# cslr_usb_001 register map
Vendor: Texas Instruments
Address unit: 16 bits
Registers are 16-bit, access not given, reset 0x0 unless marked. A register's access mark holds for its fields unless they carry their own. Offsets are as the file gives them; [hi:lo] are bit positions; {n}, {i} and the like mark numbered series; 'fields as' and 'values as' point back to an identical list.

## USB (part 2 of 2) — USB2.0 OTG Controller
{0x422+4i} FIFO{i}R2 rw (i=0..4) — Transmit and Receive FIFO Register 2 for Endpoint {i}
  [15:0] DATA — Writing to these addresses loads data into the Transmit FIFO for the corresponding endpoint. Reading from these addresses unloads data from the Receive FIFO for the corresponding endpoint. Most-significant bits.
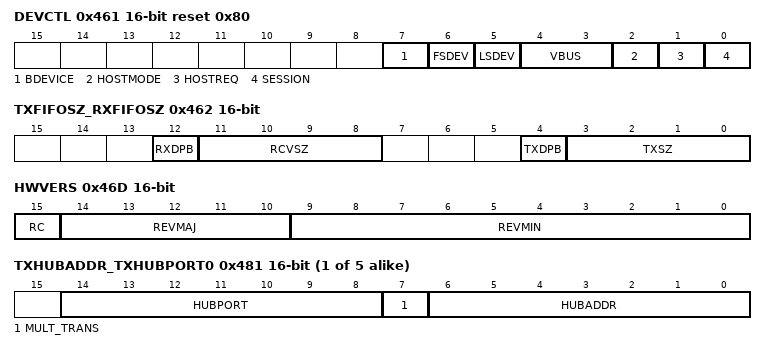
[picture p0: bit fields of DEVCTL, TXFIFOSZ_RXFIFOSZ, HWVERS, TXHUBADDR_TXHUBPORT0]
0x461 DEVCTL reset 0x80 — OTG Device Control Register
  [7] BDEVICE ro — This Read-only bit indicates whether the USB controller is operating as the A device or the B device 0: A device 1: B device Only valid while a session is in progress
    0=ADEVICE; 1=BDEVICE
  [6] FSDEV ro — This Read-only bit is set when a full-speed or high-speed device has been detected being connected to the port (High-speed devices are distinguished from full-speed by checking for high-speed chirps when the device is reset) Only valid in Host mode
  [5] LSDEV ro — This Read-only bit is set when a low-speed device has been detected being connected to the port Only valid in Host mode
  [4:3] VBUS ro — These Read-only bits encode the current VBus level as follows ----------------------------------------------------------------------------- VBus[1] VBus[0] Meaning ------------------------------------------------------------------------------ 0 0 Below SessionEnd 0 1 Above SessionEnd, below AValid 1 0 Above AValid, below VBusValid 1 1 Above VBusValid
    0=BELOW (Below Session End); 1=BELOWAVALID (Above Session End, below Avalid); 2=BELOWVBUSVALID (Above Avalid, below VbusValid); 3=ABOVEVBUSVALID
  [2] HOSTMODE ro — This Read-only bit is set when the USB controller is acting as a Host
  [1] HOSTREQ rw — When set, the USB controller will initiate the Host Negotiation when Suspend mode is entered. It is cleared when Host Negotiation is completed. ( B device only)
  [0] SESSION rw — When operating as an A device, this bit is set or cleared by the userto start or end a session When operating as a B device, this bit is set/cleared by the USB controller when a session starts/ends It is also set by the user to initiate the Session Request Protocol. When the USB controller is in Suspend mode, the bit may be cleared by the user to perform a software disconnect
0x462 TXFIFOSZ_RXFIFOSZ — Tx RX Endpoint FIFO Size(Index register set to select Endpoints 1 - 4 only)
  [12] RXDPB rw — Double packet buffering enable
    0=SINGLE (Single packet buffering is supported); 1=DOUBLE (Double packet buffering is enabled)
  [11:8] RCVSZ ro — Maximum packet size to be allowed(before any splitting within the FIFO of Bulk packets prior to transmission) If m = SZ[3:0], the FIFO size is calculated as 2(m+3) for single packet buffering and 2(m+4) for dual packet buffering
  [4] TXDPB rw — Double packet buffering enable
    values as RXDPB
  [3:0] TXSZ ro — Maximum packet size to be allowed(before any splitting within the FIFO of Bulk packets prior to transmission) If m = SZ[3:0], the FIFO size is calculated as 2(m+3) for single packet buffering and 2(m+4) for dual packet buffering
0x465 TXFIFOADDR — Tx Endpoint FIFO Address(Index register set to select Endpoints 1 - 4 only)
  [12:0] ADDR rw — Start Address of endpoint FIFO in units of 8 bytes If m = ADDR[12:0] then the start address is 8*m
0x466 RXFIFOADDR — Rx Endpoint FIFO Address(Index register set to select Endpoints 1 - 4 only)
  fields as TXFIFOADDR
0x46D HWVERS — The hardware version register (HWVERS) contains the RTL major and minor version numbers for the USB 2.0 OTG controller module. The RTL version number is REVMAJ.REVMIN.
  [15] RC — Set to 1 if RTL is used from a Release Candidate, rather than from a full release of the core. (access N)
  [14:10] REVMAJ ro — Major version of RTL. Range is 0-31.
  [9:0] REVMIN ro — Minor version of RTL. Range is 0-999.
{0x480+8i} TXFUNCADDR{i} (i=0..4) — Address of the target function that has to be accessed through the associated Tx Endpoint
  [6:0] FUNCADDR rw — Address of target function
{0x481+8i} TXHUBADDR_TXHUBPORT{i} (i=0..4) — Address and Port of the hub that has to be accessed through the associated Tx Endpoint. This is used only when full speed or low speed device is connected via a USB2.0 high speed hub
  [14:8] HUBPORT rw — Port number of the hub
  [7] MULT_TRANS rw — Set to '1' if hub has multiple transaction translators. Set to '0' if only single transaction translator is available
  [6:0] HUBADDR rw — Address of hub
{0x484+8i} RXFUNCADDR{i} (i=0..4) — Address of the target function that has to be accessed through the associated Rx Endpoint
  [6:0] FUNCADDR rw — Address of target function
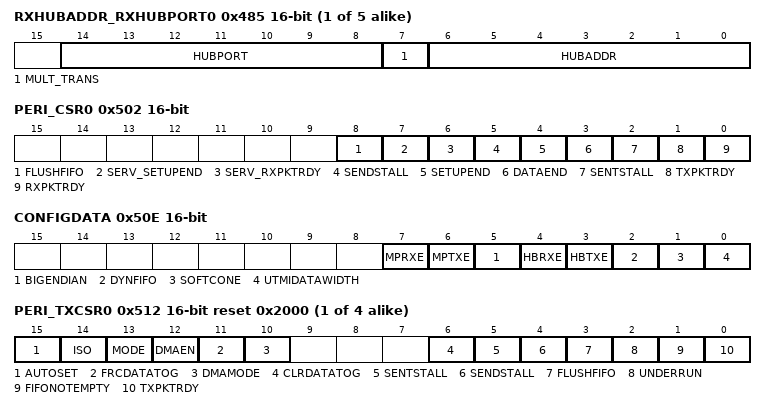
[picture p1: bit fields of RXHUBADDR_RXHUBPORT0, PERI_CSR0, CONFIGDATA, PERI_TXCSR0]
{0x485+8i} RXHUBADDR_RXHUBPORT{i} (i=0..4) — Address and Port of the hub that has to be accessed through the associated Rx Endpoint. This is used only when full speed or low speed device is connected via a USB2.0 high speed hub
  fields as TXHUBADDR_TXHUBPORT0
0x502 PERI_CSR0 — Control Status register for Endpoint 0 in Peripheral mode.
  [8] FLUSHFIFO wo — Set this bit to flush the next packet to be transmitted/read from the Endpoint 0 FIFO. The FIFO pointer is reset and the TXPKTRDY/RXPKTRDY bit (below) is cleared Note: FLUSHFIFO has no effect unless TXPKTRDY/RXPKTRDY is set
  [7] SERV_SETUPEND wo — Set this bit to clear the SETUPEND bit. It is cleared automatically
  [6] SERV_RXPKTRDY wo — Set this bit to clear the RXPKTRDY bit. It is cleared automatically
  [5] SENDSTALL wo — Set this bit to terminate the current transaction. The STALL handshake will be transmitted and then this bit will be cleared automatically
  [4] SETUPEND ro — This bit will be set when a control transaction ends before the DATAEND bit has been set. An interrupt will be generated and the FIFO flushed at this time. The bit is cleared by the user writing a 1 to the SERV_SETUPEND bit
  [3] DATAEND wo — Set this bit 1. When setting TXPKTRDY for the last data packet 2. When clearing RXPKTRDY after unloading the last data packet 3. When setting TXPKTRDY for a zero length data packet It is cleared automatically
  [2] SENTSTALL rw — This bit is set when a STALL handshake is transmitted. This bit should be cleared by the user
  [1] TXPKTRDY rw — Set this bit after loading a data packet into the FIFO. It is cleared automatically when the data packet has been transmitted. An interrupt is generated (if enabled) when the bit is cleared
  [0] RXPKTRDY ro — This bit is set when a data packet has been received. An interrupt is generated when this bit is set. This bit is cleared by setting the SERV_RXPKTRDY bit
0x509 COUNT0 — Number of received bytes in Endpoint 0 FIFO.
  [6:0] EP0RXCOUNT ro — Indicates the number of received data bytes in the Endpoint 0 FIFO The value returned changes as the contents of the FIFO change and is only valid while RXPKTRDY of PERI_CSR0 or HOST_CSR0 is set
0x50E CONFIGDATA — Returns details of core configuration
  [7] MPRXE — When set to '1', automatic amalgamation of bulk packets is selected (access N)
  [6] MPTXE ro — When set to '1', automatic splitting of bulk packets is selected
  [5] BIGENDIAN ro — When set to 1 indicates Big Endian ordering is selected
  [4] HBRXE ro — When set to 1 indicates High-bandwidth Rx ISO Endpoint Support selected
  [3] HBTXE ro — When set to 1 indicates High-bandwidth Tx ISO Endpoint Support selected
  [2] DYNFIFO ro — When set to 1 indicates Dynamic FIFO Sizing option selected
  [1] SOFTCONE ro — When set to 1 indicates Soft Connect/Disconnect option selected
  [0] UTMIDATAWIDTH ro — Indicates selected UTMI data width 0: 8 bits 1: 16 bits
{0x511+0x10*i} TXMAXP{i} (i=0..3) — Maximum packet size for peripheral/host Tx endpoint
  [10:0] MAXPAYLOAD rw — The maximum payload transmitted in a single transaction The value set can be up to 1024 bytes but is subject to the constraints placed by the USB Specification on packet sizes for Bulk, Interrupt and Isochronous transfers in Full-speed and High-speed operations The value written to this register should match the wMaxPacketSize field of the Standard Endpoint Descriptor for the associated endpoint. A mismatch could cause unexpected results
{0x512+0x10*i} PERI_TXCSR{i} reset 0x2000 (i=0..3) — Control Status register for peripheral Tx endpoint. (Index register set to select Endpoints 1 4)
  [15] AUTOSET rw — When this bit is set, TXPKTRDY will be automatically set when data of the maximum packet size (value in TXMAXP is loaded into the Tx FIFO. If a packet of less than the maximum packet size is loaded, then TXPKTRDY will have to be set manually. TXPKTRDY will also be automatically set when the first of two packets in the Tx FIFO has been sent and the second packet is the maximum packet size
  [14] ISO rw — Set this bit to enable the Tx endpoint for Isochronous transfers, and clear it to enable the Tx endpoint for Bulk or Interrupt transfers
  [13] MODE rw — Set this bit to enable the endpoint direction as Tx, and clear the bit to enable it as Rx Note: This bit only has any effect where the same endpoint FIFO is used for both Tx and Rx transactions
  [12] DMAEN rw — Set this bit to enable the DMA request for the Tx endpoint
  [11] FRCDATATOG rw — Set this bit to force the endpoint data toggle to switch and the data packet to be cleared from the FIFO, regardless of whether an ACK was received. This can be used by Interrupt Tx endpoints that are used to communicate rate feedback for Isochronous endpoints
  [10] DMAMODE rw — This bit should always be 0
  [6] CLRDATATOG wo — Write a 1 to this bit to reset the endpoint data toggle to 0
  [5] SENTSTALL rw — This bit is set automatically when a STALL handshake is transmitted. The FIFO is flushed and the TXPKTRDY bit is cleared (see below). The user should clear this bit
  [4] SENDSTALL rw — Write a 1 to this bit to issue a STALL handshake to an IN token. Clear this bit to terminate the stall condition Note: This bit has no effect where the endpoint is being used for Isochronous transfers
  [3] FLUSHFIFO wo — Write a 1 to this bit to flush the next packet to be transmitted from the endpoint Tx FIFO. The FIFO pointer is reset and the TXPKTRDY bit (below) is cleared. Note: FlushFIFO has no effect unless TXPKTRDY is set. Also note that, if the FIFO is double-buffered, FlushFIFO may need to be set twice to completely clear the FIFO
  [2] UNDERRUN rw — This bit is set automatically if an IN token is received when TXPKTRDY is not set. The user should clear this bit
  [1] FIFONOTEMPTY rw — This bit is set when there is at least 1 packet in the Tx FIFO. The user should clear this bit
  [0] TXPKTRDY rw — Set this bit after loading a data packet into the FIFO. It is cleared automatically when a data packet has been transmitted. An interrupt is generated (if enabled) when the bit is cleared
{0x515+0x10*i} RXMAXP{i} (i=0..3) — Maximum packet size for peripheral/host Rx endpoint
  [10:0] MAXPAYLOAD rw — Defines the maximum amount of data that can be transferred through the selected Rx endpoint in a single frame / microframe (High-speed transfers) The value set can be up to 1024 bytes but is subject to the constraints placed by the USB Specification on packet sizes for Bulk, Interrupt and Isochronous transfers in Full-speed and High-speed operations The value written to this register should match the wMaxPacketSize field of the Standard Endpoint Descriptor for the associated endpoint. A mismatch could cause unexpected results
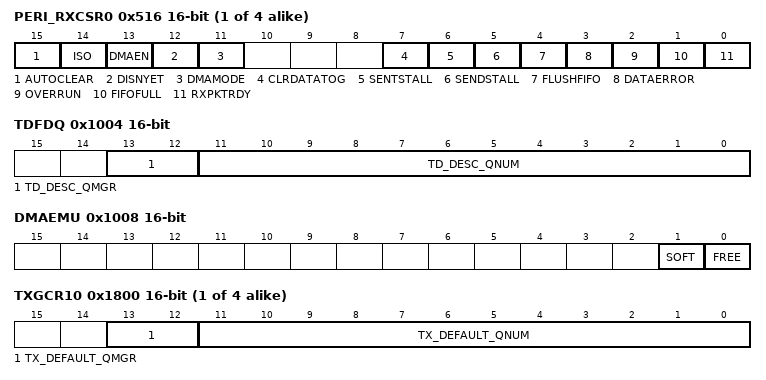
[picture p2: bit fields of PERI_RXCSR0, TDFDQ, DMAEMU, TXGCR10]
{0x516+0x10*i} PERI_RXCSR{i} (i=0..3) — Control Status register for peripheral Rx endpoint.
  [15] AUTOCLEAR rw — When this bit is set, the RXPKTRDY bit will be automatically cleared when a packet of RXMAXP bytes has been unloaded from the Rx FIFO. When packets of less than the maximum packet size are unloaded, RXPKTRDY will have to be cleared manually
  [14] ISO rw — Set this bit to enable the Rx endpoint for Isochronous transfers, and clear it to enable the Rx endpoint for Bulk/Interrupt transfers
  [13] DMAEN rw — Set this bit to enable the DMA request for the Rx endpoints
  [12] DISNYET rw — Set this bit to disable the sending of NYET handshakes. When set, all successfully received Rx packets are ACK'd including at the point at which the FIFO becomes full Note: This bit only has any effect in High-speed mode, in which mode it should be set for all Interrupt endpoints
  [11] DMAMODE rw — This bit should always be 0
  [7] CLRDATATOG wo — Write a 1 to this bit to reset the endpoint data toggle to 0
  [6] SENTSTALL rw — This bit is set when a STALL handshake is transmitted. The FIFO is flushed and the TXPKTRDY bit is cleared (see below). The user should clear this bit
  [5] SENDSTALL rw — Write a 1 to this bit to issue a STALL handshake Clear this bit to terminate the stall condition Note: This bit has no effect where the endpoint is being used for Isochronous transfers
  [4] FLUSHFIFO wo — Write a 1 to this bit to flush the next packet to be read from the endpoint Rx FIFO. The FIFO pointer is reset and the RXPKTRDY bit (below) is cleared Note: FLUSHFIFO has no effect unless RXPKTRDY is set. Also note that, if the FIFO is double-buffered, FLUSHFIFO may need to be set twice to completely clear the FIFO
  [3] DATAERROR ro — This bit is set when RXPKTRDY is set if the data packet has a CRC or bit-stuff error. It is cleared when RXPKTRDY is cleared Note: This bit is only valid when the endpoint is operating in ISO mode. In Bulk mode, it always returns zero.
  [2] OVERRUN rw — This bit is set if an OUT packet cannot be loaded into the Rx FIFO. The user should clear this bit Note: This bit is only valid when the endpoint is operating in ISO mode. In Bulk mode, it always returns zero
  [1] FIFOFULL ro — This bit is set when no more packets can be loaded into the Rx FIFO
  [0] RXPKTRDY rw — This bit is set when a data packet has been received. The user should clear this bit when the packet has been unloaded from the Rx FIFO. An interrupt is generated when the bit is set
{0x519+0x10*i} RXCOUNT{i} (i=0..3) — Number of bytes in host Rx endpoint FIFO. (Index register set to select Endpoints 1 - 4)
  [12:0] EPRXCOUNT ro — Holds the number of received data bytes in the packet in the Rx FIFO The value returned changes as the contents of the FIFO change and is only valid while RXPKTRDY of PERI_RXCSR or HOST_RXCSR is set
0x1000 DMAREVID1 ro reset 0x1900 — The CDMA revision identification register (DMAREVID) contains the revision for the module.
  [15:0] REV — Revision ID of the CPPI DMA (CDMA) module. Least-significant bits.
0x1001 DMAREVID2 ro reset 0x53 — The CDMA revision identification register (DMAREVID) contains the revision for the module.
  [15:0] REV — Revision ID of the CPPI DMA (CDMA) module. Most-significant bits.
0x1004 TDFDQ — The CDMA teardown free descriptor queue control register (TDFDQ) is used to inform the DMA of the location in memory or descriptor array which is to be used for signaling of a teardown complete for each transmit and receive channel.
  [13:12] TD_DESC_QMGR rw — Controls which of the four queue managers the DMA accesses to allocate a channel teardown descriptor from the teardown descriptor queue.
  [11:0] TD_DESC_QNUM rw — Controls which of the 2K queues in the indicated queue manager should be read to allocate the channel teardown descriptors.
0x1008 DMAEMU — The CDMA emulation controls the behavior of the DMA when the emususp input is asserted.
  [1] SOFT rw, [0] FREE rw
{0x16C0+0x20*i} TXGCR{i} (i=10..13) — The Tx Channel Configuration Registers are used to initialize the behavior of each of the Tx DMA channels
  [13:12] TX_DEFAULT_QMGR wo — This field controls the default queue number within the selected queue manager number that will be used to queue teardown descriptors back to the host.
  [11:0] TX_DEFAULT_QNUM wo — This field controls the default queue number within the selected queue manager onto which teardown descriptors will be queued back to the host.
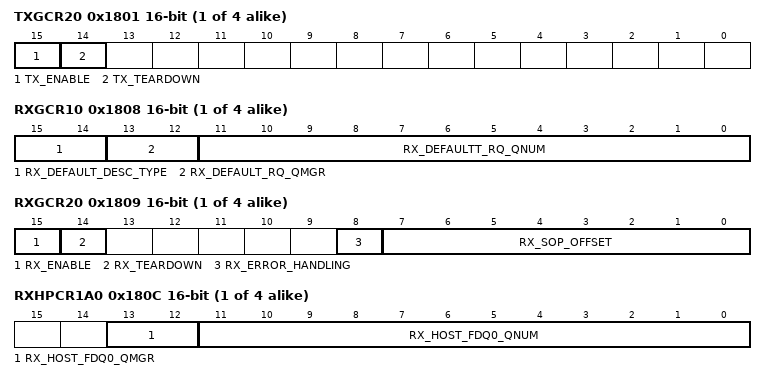
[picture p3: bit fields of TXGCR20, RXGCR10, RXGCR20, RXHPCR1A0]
{0x1581+0x20*i} TXGCR{i} (i=20..23) — The Tx Channel Configuration Registers are used to initialize the behavior of each of the Tx DMA channels
  [15] TX_ENABLE rw — Channel control. The TX_ENABLE field is cleared after a channel teardown is complete.
    0=DISABLE (Disabled channel); 1=ENABLE (Enables channel)
  [14] TX_TEARDOWN rw — Setting this bit requests the channel to be torn down. The TX_TEARDOWN field remains set after a channel teardown is complete.
{0x16C8+0x20*i} RXGCR{i} (i=10..13) — The Rx Channel Configuration Registers are used to initialize the behavior of each of the Rx DMA channels
  [15:14] RX_DEFAULT_DESC_TYPE — Indicates the default descriptor type to use. The actual descriptor type that is used for reception can be overridden by information provided in the CPPI FIFO data block. (access N)
    0=RSV1 (Reserved); 1=HOST; 2=RSV2 (Reserved); 3=RSV3 (Reserved)
  [13:12] RX_DEFAULT_RQ_QMGR — Indicates the default receive queue manager that this channel should use. The actual receive queue manager index can be overridden by information provided in the CPPI FIFO data block. (access N)
  [11:0] RX_DEFAULTT_RQ_QNUM rw — Indicates the default receive queue that this channel should use. The actual receive queue that is used for reception can be overridden by information provided in the CPPI FIFO data block.
{0x1589+0x20*i} RXGCR{i} (i=20..23) — The Rx Channel Configuration Registers are used to initialize the behavior of each of the Rx DMA channels
  [15] RX_ENABLE rw — This field enables or disables the channel.
    0=DISABLE (Disables channel); 1=ENABLE (Enables channel)
  [14] RX_TEARDOWN rw — This field indicates whether or not an Rx teardown operation is complete. This field should be cleared when a channel is initialized. This field will be set after a channel teardown is complete.
  [8] RX_ERROR_HANDLING rw — Controls the error handling mode for the channel and is only used when channel errors (i.e. descriptor or buffer starvation occur):
    0=DROPPCKT (Starvation errors result in dropping packet and reclaiming any used descriptor or buffer resources back to the original queues/pools they were allocated to.); 1=RETRYPCKT (Starvation errors result in subsequent retry of the descriptor allocation operation. In this mode, the DMA will return to the IDLE state without saving its internal operational state back to the internal state RAM and without issuing an advance operation on the FIFO interface. This results in the DMA re-initiating the FIFO block transfer at a later time with the intention that additional free buffers and/or descriptors will have been added.)
  [7:0] RX_SOP_OFFSET rw — Number of bytes that are to be skipped in the SOP buffer before beginning to write the payload.
{0x180C+0x20*i} RXHPCR1A{i} (i=0..3) — The Rx Channel Host Packet Configuration Registers are used to initialize the behavior of each of the Rx DMA channels for reception of host type packets
  [13:12] RX_HOST_FDQ0_QMGR — This field specifies which Buffer Manager should be used for the 1st Rx buffer in a host type packet (access N)
  [11:0] RX_HOST_FDQ0_QNUM rw — This field specifies which Free Descriptor / Buffer Pool should be used for the 1st Rx buffer in a host type packet
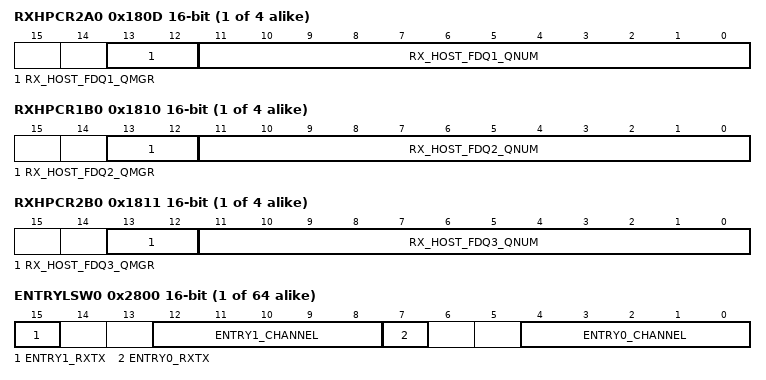
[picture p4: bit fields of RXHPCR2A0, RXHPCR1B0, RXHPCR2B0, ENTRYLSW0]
{0x180D+0x20*i} RXHPCR2A{i} (i=0..3) — The Rx Channel Host Packet Configuration Registers are used to initialize the behavior of each of the Rx DMA channels for reception of host type packets
  [13:12] RX_HOST_FDQ1_QMGR — This field specifies which Buffer Manager should be used for the 2nd Rx buffer in a host type packet (access N)
  [11:0] RX_HOST_FDQ1_QNUM rw — This field specifies which Free Descriptor / Buffer Pool should be used for the 2nd Rx buffer in a host type packet
{0x1810+0x20*i} RXHPCR1B{i} (i=0..3) — The Rx Channel Host Packet Configuration Registers are used to initialize the behavior of each of the Rx DMA channels for reception of host type packets
  [13:12] RX_HOST_FDQ2_QMGR — This field specifies which Buffer Manager should be used for the 3rd Rx buffer in a host type packet (access N)
  [11:0] RX_HOST_FDQ2_QNUM rw — This field specifies which Free Descriptor / Buffer Pool should be used for the 3rd Rx buffer in a host type packet
{0x1811+0x20*i} RXHPCR2B{i} (i=0..3) — The Rx Channel Host Packet Configuration Registers are used to initialize the behavior of each of the Rx DMA channels for reception of host type packets
  [13:12] RX_HOST_FDQ3_QMGR — This field specifies which Buffer Manager should be used for the 4th Rx buffer in a host type packet (access N)
  [11:0] RX_HOST_FDQ3_QNUM rw — This field specifies which Free Descriptor / Buffer Pool should be used for the 4th Rx buffer in a host type packet
0x2000 DMA_SCHED_CTRL1 — CDMA Scheduler Control Register 1
  [7:0] LAST_ENTRY rw — Last valid entry in the scheduler table. 0 = 1 entry 1 = 2 entries & 254 = 255 entries 255 = 256 entries
0x2001 DMA_SCHED_CTRL2 — CDMA Scheduler Control Register 2
  [15] ENABLE rw — This is the enable bit for the scheduler.
    0=ENABLED (Scheduler is disabled and will no longer fetch entries from the scheduler table or pass credits to the DMA controller); 1=DISABLED (Scheduler is enabled. This bit should only be set after the table has been initialized.)
{0x2800+4i} ENTRYLSW{i} (i=0..63) — CDMA Scheduler Table Word Register LSW
  [15] ENTRY1_RXTX wo — This entry is for a transmit or a receive channel.
    0=XMTCH (Transmit channel); 1=RCVCH (Receive channel)
  [12:8] ENTRY1_CHANNEL wo — Indicates the channel number that is to be given an opportunity to transfer data. If this is a transmit entry, the DMA will be presented with a scheduling credit for that exact transmit channel. If this is a receive entry, the DMA will be presented with a scheduling credit for the receive FIFO that is associated with this channel. For receive FIFOs which carry traffic for more than one receive DMA channel, the exact channel number that is given in the receive credit will actually be the channel number which is currently on the head element of that Rx FIFO, which is not necessarily the channel number given in the scheduler table entry.
  [7] ENTRY0_RXTX wo — This entry is for a transmit or a receive channel.
    0=XMTCH (Transmit channel); 1=RCVCH (Receive channel)
  [4:0] ENTRY0_CHANNEL wo — Indicates the channel number that is to be given an opportunity to transfer data. If this is a transmit entry, the DMA will be presented with a scheduling credit for that exact transmit channel. If this is a receive entry, the DMA will be presented with a scheduling credit for the receive FIFO that is associated with this channel. For receive FIFOs which carry traffic for more than one receive DMA channel, the exact channel number that is given in the receive credit will actually be the channel number which is currently on the head element of that Rx FIFO, which is not necessarily the channel number given in the scheduler table entry.
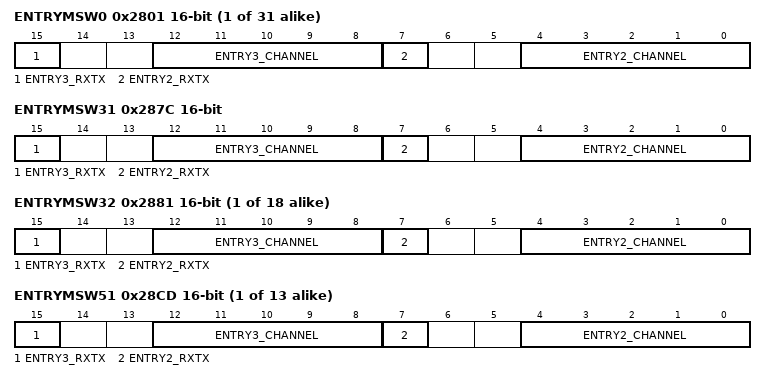
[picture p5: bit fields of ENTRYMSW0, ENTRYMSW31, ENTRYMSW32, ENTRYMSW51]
{0x2801+4i} ENTRYMSW{i} (i=0..30) — CDMA Scheduler Table Word Register MSW
  [15] ENTRY3_RXTX wo — This entry is for a transmit or a receive channel.
    0=XMTCH (Transmit channel); 1=RCVCH (Receive channel)
  [12:8] ENTRY3_CHANNEL wo — Indicates the channel number that is to be given an opportunity to transfer data. If this is a transmit entry, the DMA will be presented with a scheduling credit for that exact transmit channel. If this is a receive entry, the DMA will be presented with a scheduling credit for the receive FIFO that is associated with this channel. For receive FIFOs which carry traffic for more than one receive DMA channel, the exact channel number that is given in the receive credit will actually be the channel number which is currently on the head element of that Rx FIFO, which is not necessarily the channel number given in the scheduler table entry.
  [7] ENTRY2_RXTX wo — This entry is for a transmit or a receive channel.
    0=XMTCH (Transmit channel); 1=RCVCH (Receive channel)
  [4:0] ENTRY2_CHANNEL wo — Indicates the channel number that is to be given an opportunity to transfer data. If this is a transmit entry, the DMA will be presented with a scheduling credit for that exact transmit channel. If this is a receive entry, the DMA will be presented with a scheduling credit for the receive FIFO that is associated with this channel. For receive FIFOs which carry traffic for more than one receive DMA channel, the exact channel number that is given in the receive credit will actually be the channel number which is currently on the head element of that Rx FIFO, which is not necessarily the channel number given in the scheduler table entry.
0x287C ENTRYMSW31 — CDMA Scheduler Table Word Register MSW
  fields as ENTRYMSW0
{0x2801+4i} ENTRYMSW{i} (i=32..49) — CDMA Scheduler Table Word Register MSW
  fields as ENTRYMSW0
{0x2801+4i} ENTRYMSW{i} (i=51..63) — CDMA Scheduler Table Word Register MSW
  fields as ENTRYMSW0
0x4000 QMGRREVID1 ro reset 0x1200 — Queue Manager Revision Identification Register 1
  [15:0] REV — Revision ID of the queue manager. Least-significant bits.
0x4001 QMGRREVID2 ro reset 0x52 — Queue Manager Revision Identification Register 2
  [15:0] REV — Revision ID of the queue manager. Most-significant bits.
0x4008 DIVERSION1 — Queue Manager Queue Diversion Register 1
  [13:0] SOURCE_QNUM wo — Source Queue Number
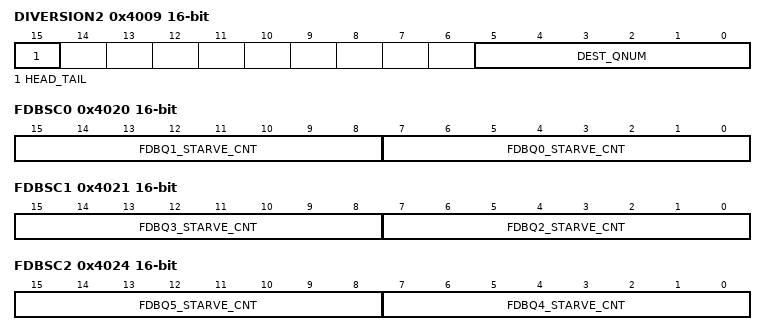
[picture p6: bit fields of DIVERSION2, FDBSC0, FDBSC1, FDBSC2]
0x4009 DIVERSION2 — Queue Manager Queue Diversion Register 2
  [15] HEAD_TAIL wo — Indicates whether queue contents should be merged on to the head or tail of the destination queue.
    0=HEAD; 1=TAIL
  [5:0] DEST_QNUM wo — Destination Queue Number
0x4020 FDBSC0 ro — Queue Manager Free Descriptor/Buffer Starvation Count Register 0
  [15:8] FDBQ1_STARVE_CNT — This field increments each time the Free Descriptor Buffer Queue 1 is read while it is empty. This field is cleared when read.
  [7:0] FDBQ0_STARVE_CNT — This field increments each time the Free Descriptor Buffer Queue 0 is read while it is empty. This field is cleared when read.
0x4021 FDBSC1 ro — Queue Manager Free Descriptor/Buffer Starvation Count Register 1
  [15:8] FDBQ3_STARVE_CNT — This field increments each time the Free Descriptor Buffer Queue 3 is read while it is empty. This field is cleared when read.
  [7:0] FDBQ2_STARVE_CNT — This field increments each time the Free Descriptor Buffer Queue 2 is read while it is empty. This field is cleared when read.
0x4024 FDBSC2 ro — Queue Manager Free Descriptor/Buffer Starvation Count Register 2
  [15:8] FDBQ5_STARVE_CNT — This field increments each time the Free Descriptor Buffer Queue 5 is read while it is empty. This field is cleared when read.
  [7:0] FDBQ4_STARVE_CNT — This field increments each time the Free Descriptor Buffer Queue 4 is read while it is empty. This field is cleared when read.
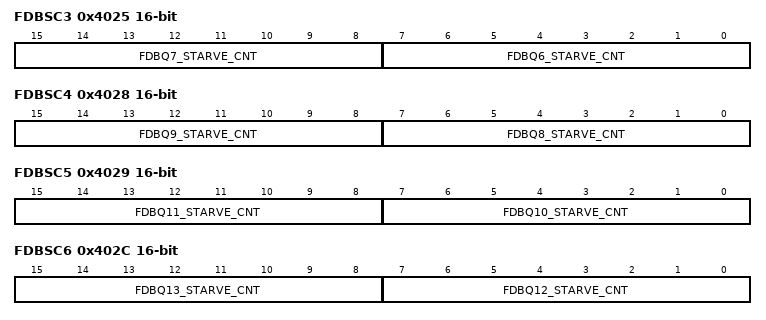
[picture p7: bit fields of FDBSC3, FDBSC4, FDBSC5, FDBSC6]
0x4025 FDBSC3 ro — Queue Manager Free Descriptor/Buffer Starvation Count Register 3
  [15:8] FDBQ7_STARVE_CNT — This field increments each time the Free Descriptor Buffer Queue 7 is read while it is empty. This field is cleared when read.
  [7:0] FDBQ6_STARVE_CNT — This field increments each time the Free Descriptor Buffer Queue 6 is read while it is empty. This field is cleared when read.
0x4028 FDBSC4 ro — Queue Manager Free Descriptor/Buffer Starvation Count Register 4
  [15:8] FDBQ9_STARVE_CNT — This field increments each time the Free Descriptor Buffer Queue 9 is read while it is empty. This field is cleared when read.
  [7:0] FDBQ8_STARVE_CNT — This field increments each time the Free Descriptor Buffer Queue 8 is read while it is empty. This field is cleared when read.
0x4029 FDBSC5 ro — Queue Manager Free Descriptor Buffer Starvation Count Register 5
  [15:8] FDBQ11_STARVE_CNT — This field increments each time the Free Descriptor Buffer Queue 11 is read while it is empty. This field is cleared when read.
  [7:0] FDBQ10_STARVE_CNT — This field increments each time the Free Descriptor Buffer Queue 10 is read while it is empty. This field is cleared when read.
0x402C FDBSC6 ro — Queue Manager Free Descriptor/Buffer Starvation Count Register 6
  [15:8] FDBQ13_STARVE_CNT — This field increments each time the Free Descriptor Buffer Queue 13 is read while it is empty. This field is cleared when read.
  [7:0] FDBQ12_STARVE_CNT — This field increments each time the Free Descriptor Buffer Queue 12 is read while it is empty. This field is cleared when read.
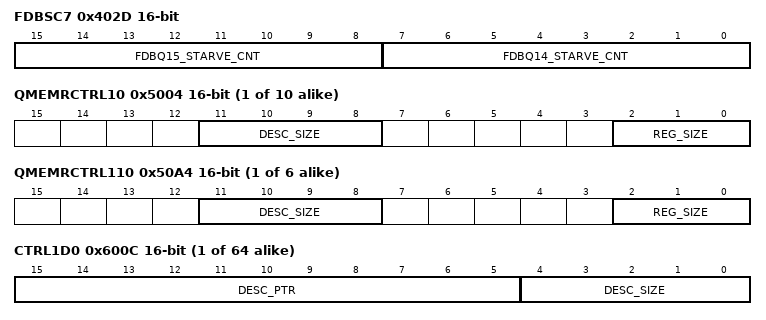
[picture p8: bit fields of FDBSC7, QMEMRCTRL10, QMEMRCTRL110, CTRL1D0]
0x402D FDBSC7 ro — Queue Manager Free Descriptor/Buffer Starvation Count Register 7
  [15:8] FDBQ15_STARVE_CNT — This field increments each time the Free Descriptor Buffer Queue 15 is read while it is empty. This field is cleared when read.
  [7:0] FDBQ14_STARVE_CNT — This field increments each time the Free Descriptor Buffer Queue 14 is read while it is empty. This field is cleared when read.
0x4080 LRAM0BASE1 ro — Queue Manager Linking RAM Region 0 Base Address Register 1
  [15:0] REGION0_BASE — This field stores the base address for the first region of the linking RAM. This may be anywhere in 32-bit address space but would be typically located in on-chip memory. Least-significant bits.
0x4081 LRAM0BASE2 ro — Queue Manager Linking RAM Region 0 Base Address Register 2
  [15:0] REGION0_BASE — This field stores the base address for the first region of the linking RAM. This may be anywhere in 32-bit address space but would be typically located in on-chip memory. Most-significant bits.
0x4084 LRAM0SIZE — Queue Manager Linking RAM Region 0 Size Register
  [13:0] REGION0_SIZE rw — This field indicates the number of entries that are contained in the linking RAM region 0. A descriptor with index less than region0_size value has its linking location in region 0. A descriptor with index greater than region0_size has its linking location in region 1. The queue manager will add the index (left shifted by 2 bits) to the appropriate regionX_base_addr to get the absolute 32-bit address to the linking location for a descriptor.
0x4088 LRAM1BASE1 ro — Queue Manager Linking RAM Region 1 Base Address Register 1
  [15:0] REGION1_BASE — This field stores the base address for the first region of the linking RAM. This may be anywhere in 32-bit address space but would be typically located in on-chip memory. Least-significant bits.
0x4089 LRAM1BASE2 ro — Queue Manager Linking RAM Region 1 Base Address Register 2
  [15:0] REGION1_BASE — This field stores the base address for the first region of the linking RAM. This may be anywhere in 32-bit address space but would be typically located in on-chip memory. Most-significant bits.
0x4090 PEND0 ro — Queue Manager Queue Pending Register 0
  [15:0] QPEND — This field indicates the queue pending status for queues 15-0.
0x4091 PEND1 ro — Queue Manager Queue Pending Register 1
  [15:0] QPEND — This field indicates the queue pending status for queues 31-16.
0x4094 PEND2 ro — Queue Manager Queue Pending Register 2
  [15:0] QPEND — This field indicates the queue pending status for queues 47-32.
0x4095 PEND3 ro — Queue Manager Queue Pending Register 3
  [15:0] QPEND — This field indicates the queue pending status for queues 63:48.
0x4098 PEND4 ro — Queue Manager Queue Pending Register 4
  [15:0] QPEND — This field indicates the queue pending status for queues 79-64.
0x4099 PEND5 ro — Queue Manager Queue Pending Register 5
  [15:0] QPEND — This field indicates the queue pending status for queues 95-80.
{0x4F60+0x10*i} QMEMRBASE{i} rw (i=10..19) — Queue Manager Memory Region R Base Address Register 1
  [15:0] REG — This field contains the base address of the memory region R. Least-significant bits.
{0x4EC1+0x10*i} QMEMRBASE{i} rw (i=20..29) — Queue Manager Memory Region R Base Address Register 2
  [15:0] REG — This field contains the base address of the memory region R. Most-significant bits.
{0x4F64+0x10*i} QMEMRCTRL{i} (i=10..19) — Queue Manager Memory Region R Control Register 1
  [11:8] DESC_SIZE rw — This field indicates the size of each descriptor in this memory region. It is an encoded value that specifies descriptor size as 2^(5+desc_size) number of bytes. The settings of desc_size from 9-15 are reserved.
  [2:0] REG_SIZE rw — This field indicates the size of the memory region (in terms of number of descriptors). It is an encoded value that specifies region size as 2^(5+reg_size) number of descriptors.
    0=SIZE32 (32); 1=SIZE64 (64); 2=SIZE128 (128); 3=SIZE256 (256); 4=SIZE512 (512); 5=SIZE1K (1K); 6=SIZE2K (2K); 7=SIZE4K (4K)
{0x4EC5+0x10*i} QMEMRCTRL{i} (i=20..29) — Queue Manager Memory Region R Control Register 2
  [13:0] START_INDEX rw — This field indicates where in linking RAM does the descriptor linking information corresponding to memory region R starts.
{0x49C0+0x10*i} QMEMRBASE{i} rw (i=110..115) — Queue Manager Memory Region R Base Address Register 1
  fields as QMEMRBASE10
{0x4381+0x10*i} QMEMRBASE{i} rw (i=210..215) — Queue Manager Memory Region R Base Address Register 2
  fields as QMEMRBASE20
{0x49C4+0x10*i} QMEMRCTRL{i} (i=110..115) — Queue Manager Memory Region R Control Register 1
  fields as QMEMRCTRL10
{0x4385+0x10*i} QMEMRCTRL{i} (i=210..215) — Queue Manager Memory Region R Control Register 2
  fields as QMEMRCTRL20
{0x600C+0x10*i} CTRL1D{i} rw (i=0..63) — Queue Manager Queue N Control Register 1 D
  [15:5] DESC_PTR — Descriptor pointer. It will be read as zero if the queue is empty. It will indicate a 32-bit aligned address that points to a descriptor when the queue is not empty. Least-significant bits.
  [4:0] DESC_SIZE — Descriptor Size. It is encoded in 4-byte increments with values 0 to 31 representing 24 and so on to 148 bytes. This field will return a 0x0 when an empty queue is read.
{0x600D+0x10*i} CTRL2D{i} rw (i=0..63) — Queue Manager Queue N Control Register 2 D
  [15:0] DESC_PTR — Descriptor pointer. It will be read as zero if the queue is empty. It will indicate a 32-bit aligned address that points to a descriptor when the queue is not empty. Most-significant bits.
{0x6800+0x10*i} QSTATA{i} (i=0..53) — Queue Manager Queue N Status Register A
  [13:0] QUEUE_ENTRY_COUNT ro — This field indicates how many packets are currently queued on the queue.
{0x6804+0x10*i} QSTAT1B{i} ro (i=0..63) — Queue Manager Queue N Status Register 1 B
  [15:0] QUEUE_BYTE_COUNT — This field indicates how many bytes total are contained in all of the packets which are currently queued on this queue. Least-significant bits.
{0x6805+0x10*i} QSTAT2B{i} (i=0..63) — Queue Manager Queue N Status Register 2 B
  [11:0] QUEUE_BYTE_COUNT ro — This field indicates how many bytes total are contained in all of the packets which are currently queued on this queue. Most-significant bits.
{0x6808+0x10*i} QSTAT1C{i} (i=0..63) — Queue Manager Queue N Status Register 1 C
  [13:0] PACKET_SIZE ro — This field indicates packet size and is assumed to be zero on each packet add unless the value is explicitly overwritten. This field indicates packet size for packet pop operation.
{0x6800+0x10*i} QSTATA{i} (i=55..63) — Queue Manager Queue N Status Register A
  fields as QSTATA0
0x6D60 QSTATA54 — Queue Manager Queue N Status Register A
  fields as QSTATA0
